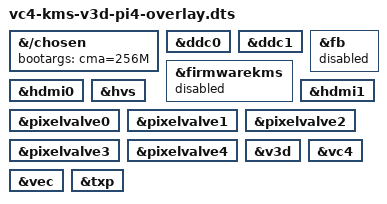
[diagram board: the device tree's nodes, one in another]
/*
 * vc4-kms-v3d-pi4-overlay.dts
 */

/dts-v1/;
/plugin/;

#include <dt-bindings/clock/bcm2835.h>

&{/chosen} {
	bootargs = "cma=256M";
};

&ddc0 {
	status = "okay";
};

&ddc1 {
	status = "okay";
};

&fb {
	status = "disabled";
};

&firmwarekms {
	status = "disabled";
};

&hdmi0 {
	status = "okay";
};

&hdmi1 {
	status = "okay";
};

&hvs {
	status = "okay";
};

&pixelvalve0 {
	status = "okay";
};

&pixelvalve1 {
	status = "okay";
};

&pixelvalve2 {
	status = "okay";
};

&pixelvalve3 {
	status = "okay";
};

&pixelvalve4 {
	status = "okay";
};

&v3d {
	status = "okay";
};

&vc4 {
	status = "okay";
};

&vec {
	status = "okay";
};

&txp {
	status = "okay";
};
